# AT32UC3A4256S device description
Architecture: AVR32_UC3; Family: AVR UC3
Registers are 32-bit, read-write, reset 0x0 unless marked. A register's access mark holds for its fields unless they carry their own. Offsets are from the block's base; [hi:lo] are bit positions; {n}, {i} and the like mark numbered series; 'fields as' and 'values as' point back to an identical list.

## USBB — USB 2.0 OTG Interface
Instances: USBB 0xfffe0000, USBB_HSB 0x0000 in hsb
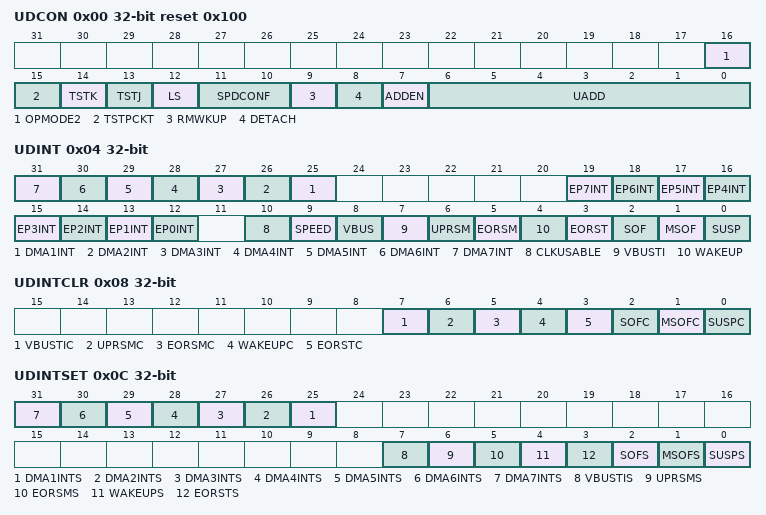
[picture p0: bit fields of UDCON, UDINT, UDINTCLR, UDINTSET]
0x00 UDCON reset 0x100 — Device General Control Register
  [16] OPMODE2, [15] TSTPCKT, [14] TSTK, [13] TSTJ, [12] LS, [11:10] SPDCONF, [9] RMWKUP, [8] DETACH, [7] ADDEN, [6:0] UADD
0x04 UDINT ro — Device Global Interupt Register
  [n+24] DMA{n}INT (n=1..7), [n+12] EP{n}INT (n=0..7), [10] CLKUSABLE, [9] SPEED, [8] VBUS, [7] VBUSTI, [6] UPRSM, [5] EORSM, [4] WAKEUP, [3] EORST, [2] SOF, [1] MSOF, [0] SUSP
0x08 UDINTCLR wo reset not defined — Device Global Interrupt Clear Register
  [7] VBUSTIC, [6] UPRSMC, [5] EORSMC, [4] WAKEUPC, [3] EORSTC, [2] SOFC, [1] MSOFC, [0] SUSPC
0x0C UDINTSET wo reset not defined — Device Global Interrupt Set Regsiter
  [n+24] DMA{n}INTS (n=1..7), [7] VBUSTIS, [6] UPRSMS, [5] EORSMS, [4] WAKEUPS, [3] EORSTS, [2] SOFS, [1] MSOFS, [0] SUSPS
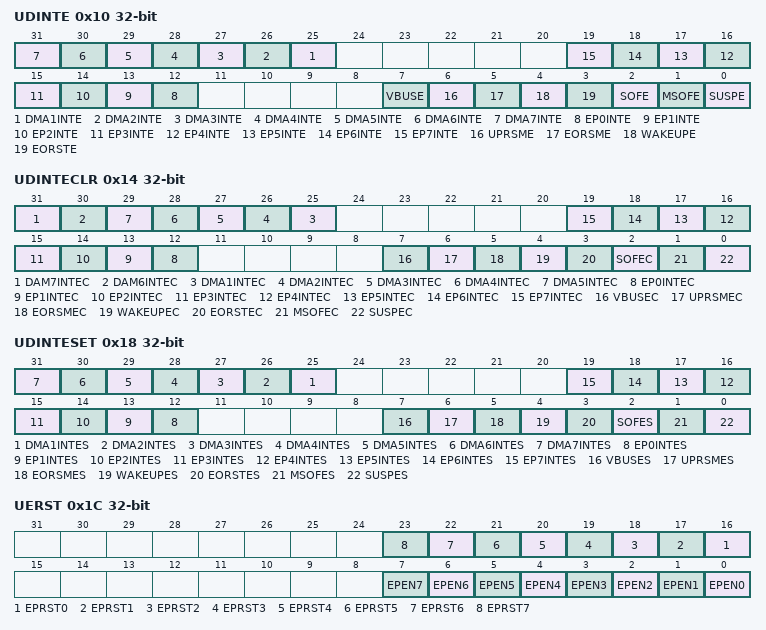
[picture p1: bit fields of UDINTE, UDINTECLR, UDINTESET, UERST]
0x10 UDINTE ro — Device Global Interrupt Enable Register
  [n+24] DMA{n}INTE (n=1..7), [n+12] EP{n}INTE (n=0..7), [7] VBUSE, [6] UPRSME, [5] EORSME, [4] WAKEUPE, [3] EORSTE, [2] SOFE, [1] MSOFE, [0] SUSPE
0x14 UDINTECLR wo reset not defined — Device Global Interrupt Enable Clear Register
  [31] DAM7INTEC, [30] DAM6INTEC, [n+24] DMA{n}INTEC (n=1..5), [n+12] EP{n}INTEC (n=0..7), [7] VBUSEC, [6] UPRSMEC, [5] EORSMEC, [4] WAKEUPEC, [3] EORSTEC, [2] SOFEC, [1] MSOFEC, [0] SUSPEC
0x18 UDINTESET wo reset not defined — Device Global Interrupt Enable Set Register
  [n+24] DMA{n}INTES (n=1..7), [n+12] EP{n}INTES (n=0..7), [7] VBUSES, [6] UPRSMES, [5] EORSMES, [4] WAKEUPES, [3] EORSTES, [2] SOFES, [1] MSOFES, [0] SUSPES
0x1C UERST — Endpoint Enable/Reset Register
  [n+16] EPRST{n} (n=0..7), [n] EPEN{n} (n=0..7)
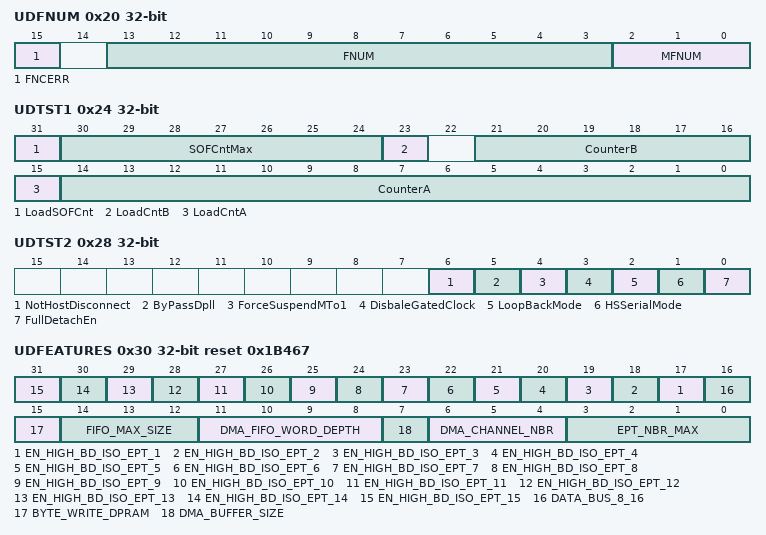
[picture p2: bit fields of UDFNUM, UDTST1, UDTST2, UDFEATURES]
0x20 UDFNUM ro — Device Frame Number Register
  [15] FNCERR, [13:3] FNUM, [2:0] MFNUM
0x24 UDTST1 — Device Test 1 Register
  [31] LoadSOFCnt, [30:24] SOFCntMax, [23] LoadCntB, [21:16] CounterB, [15] LoadCntA, [14:0] CounterA
0x28 UDTST2 — Device Test 2 Register
  [6] NotHostDisconnect, [5] ByPassDpll, [4] ForceSuspendMTo1, [3] DisbaleGatedClock, [2] LoopBackMode, [1] HSSerialMode, [0] FullDetachEn
0x2C UDVERS ro reset 0x260 — Device Version Register
0x30 UDFEATURES ro reset 0x1B467 — Device Feature Register
  [n+16] EN_HIGH_BD_ISO_EPT_{n} (n=1..15)
  [16] DATA_BUS_8_16
  [15] BYTE_WRITE_DPRAM
  [14:12] FIFO_MAX_SIZE
  [11:8] DMA_FIFO_WORD_DEPTH
  [7] DMA_BUFFER_SIZE
    0=16_BITS; 1=24_BITS
  [6:4] DMA_CHANNEL_NBR
  [3:0] EPT_NBR_MAX
0x34 UDADDRSIZE ro reset 0x1000 — Device PB address size
0x38 UDNAME1 ro reset 0x48555342 — IP Name.HUSB
0x3C UDNAME2 ro reset 0x4F5447 — IP Name, OTG
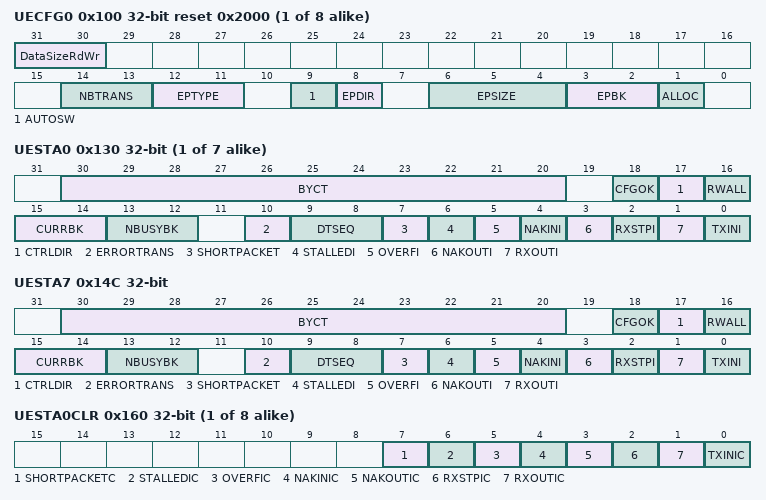
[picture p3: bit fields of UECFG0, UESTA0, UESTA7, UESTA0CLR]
{0x100+4i} UECFG{i} reset 0x2000 (i=0..7) — Endpoint Configuration Register
  [31:30] DataSizeRdWr
  [14:13] NBTRANS
  [12:11] EPTYPE
    0=CONTROL; 1=ISOCHRONOUS; 2=BULK; 3=INTERRUPT
  [9] AUTOSW
  [8] EPDIR
    0=OUT; 1=IN
  [6:4] EPSIZE
    0=8; 1=16; 2=32; 3=64; 4=128; 5=256; 6=512; 7=1024
  [3:2] EPBK
    0=SINGLE; 1=DOUBLE; 2=TRIPLE
  [1] ALLOC
{0x130+4i} UESTA{i} ro (i=0..6) — Endpoint Status Register
  [30:20] BYCT
  [18] CFGOK
  [17] CTRLDIR
    0=OUT; 1=IN
  [16] RWALL
  [15:14] CURRBK
  [13:12] NBUSYBK
  [10] ERRORTRANS
  [9:8] DTSEQ
  [7] SHORTPACKET
  [6] STALLEDI
  [5] OVERFI
  [4] NAKINI
  [3] NAKOUTI
  [2] RXSTPI
  [1] RXOUTI
  [0] TXINI
0x14C UESTA7 ro — Endpoint Status Register
  [30:20] BYCT, [18] CFGOK, [17] CTRLDIR, [16] RWALL, [15:14] CURRBK, [13:12] NBUSYBK, [10] ERRORTRANS, [9:8] DTSEQ, [7] SHORTPACKET, [6] STALLEDI, [5] OVERFI, [4] NAKINI, [3] NAKOUTI, [2] RXSTPI, [1] RXOUTI, [0] TXINI
{0x160+4i} UESTA{i}CLR wo reset not defined (i=0..7) — Endpoint Status Clear Register
  [7] SHORTPACKETC, [6] STALLEDIC, [5] OVERFIC, [4] NAKINIC, [3] NAKOUTIC, [2] RXSTPIC, [1] RXOUTIC, [0] TXINIC
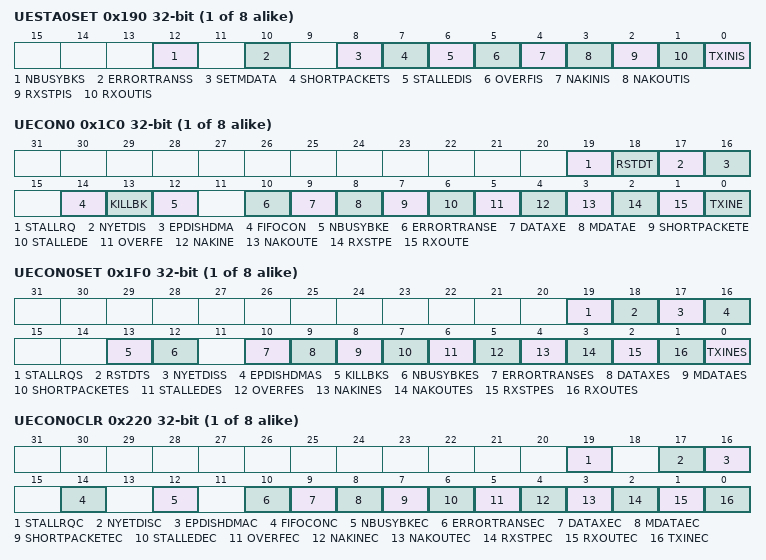
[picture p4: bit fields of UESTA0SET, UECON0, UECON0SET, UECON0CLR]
{0x190+4i} UESTA{i}SET wo reset not defined (i=0..7) — Endpoint Status Set Register
  [12] NBUSYBKS — For test/debug
  [10] ERRORTRANSS — For test/debug
  [8] SETMDATA — For test/debug
  [7] SHORTPACKETS
  [6] STALLEDIS
  [5] OVERFIS
  [4] NAKINIS
  [3] NAKOUTIS
  [2] RXSTPIS
  [1] RXOUTIS
  [0] TXINIS
{0x1C0+4i} UECON{i} ro (i=0..7) — Endpoint Control Register
  [19] STALLRQ, [18] RSTDT, [17] NYETDIS, [16] EPDISHDMA, [14] FIFOCON, [13] KILLBK, [12] NBUSYBKE, [10] ERRORTRANSE, [9] DATAXE, [8] MDATAE, [7] SHORTPACKETE, [6] STALLEDE, [5] OVERFE, [4] NAKINE, [3] NAKOUTE, [2] RXSTPE, [1] RXOUTE, [0] TXINE
{0x1F0+4i} UECON{i}SET wo reset not defined (i=0..7) — Endpoint Control Set Register
  [19] STALLRQS, [18] RSTDTS, [17] NYETDISS, [16] EPDISHDMAS, [13] KILLBKS, [12] NBUSYBKES, [10] ERRORTRANSES, [9] DATAXES, [8] MDATAES, [7] SHORTPACKETES, [6] STALLEDES, [5] OVERFES, [4] NAKINES, [3] NAKOUTES, [2] RXSTPES, [1] RXOUTES, [0] TXINES
{0x220+4i} UECON{i}CLR wo reset not defined (i=0..7) — Endpoint Control Clear Register
  [19] STALLRQC, [17] NYETDISC, [16] EPDISHDMAC, [14] FIFOCONC, [12] NBUSYBKEC, [10] ERRORTRANSEC, [9] DATAXEC, [8] MDATAEC, [7] SHORTPACKETEC, [6] STALLEDEC, [5] OVERFEC, [4] NAKINEC, [3] NAKOUTEC, [2] RXSTPEC, [1] RXOUTEC, [0] TXINEC
{0x250+4i} UEDAT{i} (i=0..7) — Endpoint Data Register
  [31:0] EP_DATA
{0x300+0x10*i} UDDMA{i}_NEXTDESC (i=1..7) — Device DMA Channel Next Descriptor Address
  [31:4] NXT_DESC_ADDR
{0x304+0x10*i} UDDMA{i}_ADDR (i=1..7) — Device DMA Channel HSB Address
  [31:0] HSB_ADDR — HSB bus Address
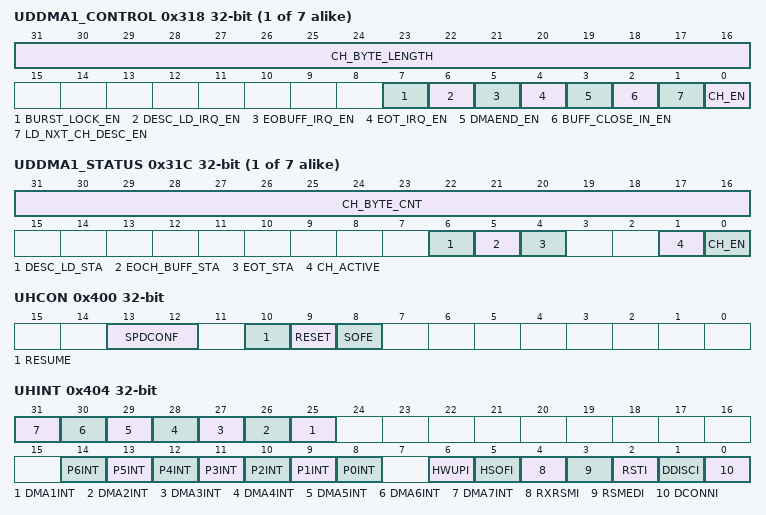
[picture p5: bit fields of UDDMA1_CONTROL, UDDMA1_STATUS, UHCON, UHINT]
{0x308+0x10*i} UDDMA{i}_CONTROL (i=1..7) — Device DMA Channel Control Register
  [31:16] CH_BYTE_LENGTH, [7] BURST_LOCK_EN, [6] DESC_LD_IRQ_EN, [5] EOBUFF_IRQ_EN, [4] EOT_IRQ_EN, [3] DMAEND_EN, [2] BUFF_CLOSE_IN_EN, [1] LD_NXT_CH_DESC_EN, [0] CH_EN
{0x30C+0x10*i} UDDMA{i}_STATUS (i=1..7) — Device DMA Channel Status Register
  [31:16] CH_BYTE_CNT, [6] DESC_LD_STA, [5] EOCH_BUFF_STA, [4] EOT_STA, [1] CH_ACTIVE, [0] CH_EN
0x400 UHCON — Host General Control Register
  [13:12] SPDCONF, [10] RESUME, [9] RESET, [8] SOFE
0x404 UHINT ro — Host Global Interrupt Register
  [n+24] DMA{n}INT (n=1..7), [n+8] P{n}INT (n=0..6), [6] HWUPI, [5] HSOFI, [4] RXRSMI, [3] RSMEDI, [2] RSTI, [1] DDISCI, [0] DCONNI
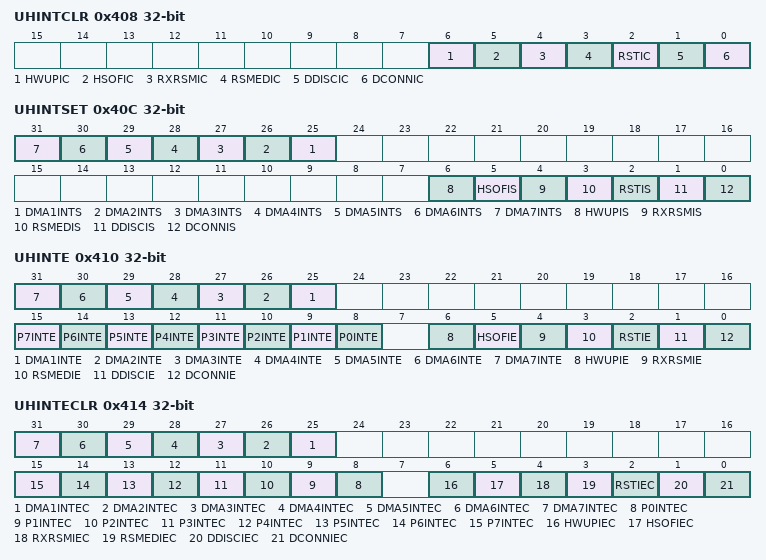
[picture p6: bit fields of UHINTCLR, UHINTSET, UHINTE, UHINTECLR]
0x408 UHINTCLR wo reset not defined — Host Global Interrrupt Clear Register
  [6] HWUPIC, [5] HSOFIC, [4] RXRSMIC, [3] RSMEDIC, [2] RSTIC, [1] DDISCIC, [0] DCONNIC
0x40C UHINTSET wo reset not defined — Host Global Interrupt Set Register
  [n+24] DMA{n}INTS (n=1..7), [6] HWUPIS, [5] HSOFIS, [4] RXRSMIS, [3] RSMEDIS, [2] RSTIS, [1] DDISCIS, [0] DCONNIS
0x410 UHINTE ro — Host Global Interrupt Enable Register
  [n+24] DMA{n}INTE (n=1..7), [n+8] P{n}INTE (n=0..7), [6] HWUPIE, [5] HSOFIE, [4] RXRSMIE, [3] RSMEDIE, [2] RSTIE, [1] DDISCIE, [0] DCONNIE
0x414 UHINTECLR wo reset not defined — Host Global Interrupt Enable Clear Register
  [n+24] DMA{n}INTEC (n=1..7), [n+8] P{n}INTEC (n=0..7), [6] HWUPIEC, [5] HSOFIEC, [4] RXRSMIEC, [3] RSMEDIEC, [2] RSTIEC, [1] DDISCIEC, [0] DCONNIEC
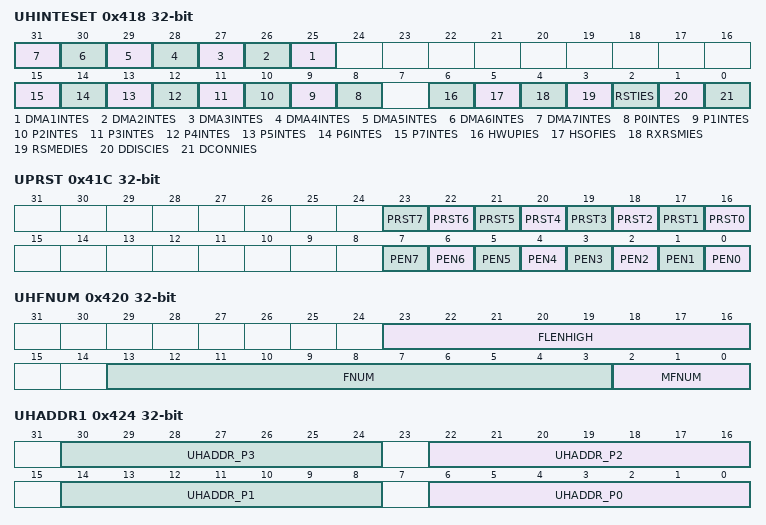
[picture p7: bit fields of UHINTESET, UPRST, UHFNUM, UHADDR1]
0x418 UHINTESET wo reset not defined — Host Global Interrupt Enable Set Register
  [n+24] DMA{n}INTES (n=1..7), [n+8] P{n}INTES (n=0..7), [6] HWUPIES, [5] HSOFIES, [4] RXRSMIES, [3] RSMEDIES, [2] RSTIES, [1] DDISCIES, [0] DCONNIES
0x41C UPRST — Pipe Reset Register
  [n+16] PRST{n} (n=0..7), [n] PEN{n} (n=0..7)
0x420 UHFNUM — Host Frame Number Register
  [23:16] FLENHIGH, [13:3] FNUM, [2:0] MFNUM
0x424 UHADDR1 — USB Host Address
  [8n+6:8n] UHADDR_P{n} (n=0..3) — USB Host Address Pipe{n} (if synthesized)
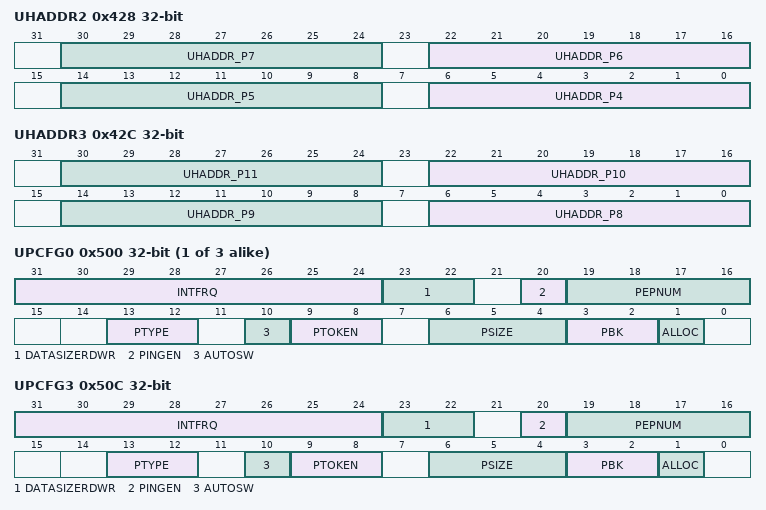
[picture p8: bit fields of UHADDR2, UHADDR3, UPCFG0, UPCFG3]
0x428 UHADDR2 — USB Host Address
  [8n-26:8n-32] UHADDR_P{n} (n=4..7) — USB Host Address Pipe{n} (if synthesized)
0x42C UHADDR3 — USB Host Address
  [8n-58:8n-64] UHADDR_P{n} (n=8..11) — USB Host Address Pipe{n} (if synthesized)
{0x500+4i} UPCFG{i} (i=0..2) — Pipe Configuration Register
  [31:24] INTFRQ
  [23:22] DATASIZERDWR
  [20] PINGEN
  [19:16] PEPNUM
  [13:12] PTYPE
    0=CONTROL; 1=ISOCHRONOUS; 2=BULK; 3=INTERRUPT
  [10] AUTOSW
  [9:8] PTOKEN
    0=SETUP; 1=IN; 2=OUT
  [6:4] PSIZE
    0=8; 1=16; 2=32; 3=64; 4=128; 5=256; 6=512; 7=1024
  [3:2] PBK
    0=SINGLE; 1=DOUBLE; 2=TRIPLE
  [1] ALLOC
0x50C UPCFG3 — Pipe Configuration Register
  [31:24] INTFRQ
  [23:22] DATASIZERDWR
  [20] PINGEN
  [19:16] PEPNUM
  [13:12] PTYPE
    0=CONTROL; 1=ISOCHRONOUS; 2=BULK; 3=INTERRUPT
  [10] AUTOSW
  [9:8] PTOKEN
    0=SETUP; 1=IN; 2=OUT
  [6:4] PSIZE
  [3:2] PBK
    0=SINGLE; 1=DOUBLE; 2=TRIPLE
  [1] ALLOC
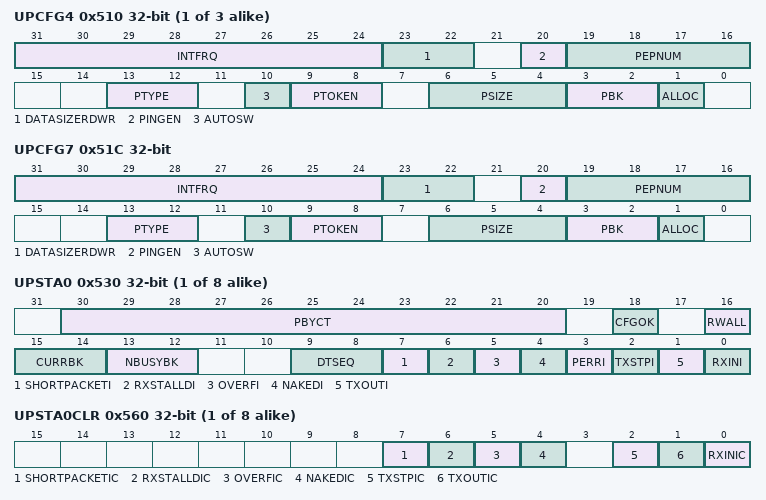
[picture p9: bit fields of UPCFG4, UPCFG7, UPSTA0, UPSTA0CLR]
{0x500+4i} UPCFG{i} (i=4..6) — Pipe Configuration Register
  fields as UPCFG0
0x51C UPCFG7 — Pipe Configuration Register
  [31:24] INTFRQ, [23:22] DATASIZERDWR, [20] PINGEN, [19:16] PEPNUM, [13:12] PTYPE, [10] AUTOSW, [9:8] PTOKEN, [6:4] PSIZE, [3:2] PBK, [1] ALLOC
{0x530+4i} UPSTA{i} ro (i=0..7) — Pipe Status Register
  [30:20] PBYCT, [18] CFGOK, [16] RWALL, [15:14] CURRBK, [13:12] NBUSYBK, [9:8] DTSEQ, [7] SHORTPACKETI, [6] RXSTALLDI, [5] OVERFI, [4] NAKEDI, [3] PERRI, [2] TXSTPI, [1] TXOUTI, [0] RXINI
{0x560+4i} UPSTA{i}CLR wo reset not defined (i=0..7) — Pipe Status Clear Register
  [7] SHORTPACKETIC, [6] RXSTALLDIC, [5] OVERFIC, [4] NAKEDIC, [2] TXSTPIC, [1] TXOUTIC, [0] RXINIC
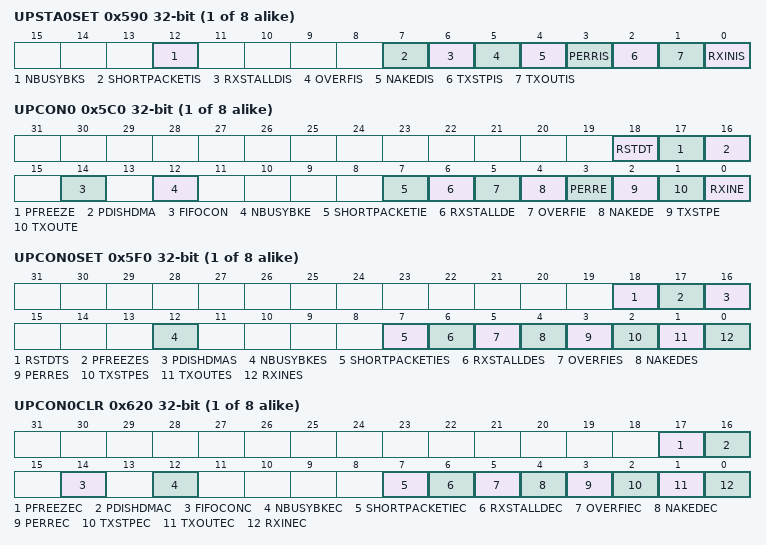
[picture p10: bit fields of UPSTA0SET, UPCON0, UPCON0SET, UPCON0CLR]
{0x590+4i} UPSTA{i}SET wo reset not defined (i=0..7) — Pipe Status Set Register
  [12] NBUSYBKS, [7] SHORTPACKETIS, [6] RXSTALLDIS, [5] OVERFIS, [4] NAKEDIS, [3] PERRIS, [2] TXSTPIS, [1] TXOUTIS, [0] RXINIS
{0x5C0+4i} UPCON{i} ro (i=0..7) — Pipe Control Register
  [18] RSTDT, [17] PFREEZE, [16] PDISHDMA, [14] FIFOCON, [12] NBUSYBKE, [7] SHORTPACKETIE, [6] RXSTALLDE, [5] OVERFIE, [4] NAKEDE, [3] PERRE, [2] TXSTPE, [1] TXOUTE, [0] RXINE
{0x5F0+4i} UPCON{i}SET wo reset not defined (i=0..7) — Pipe Control Set Register
  [18] RSTDTS, [17] PFREEZES, [16] PDISHDMAS, [12] NBUSYBKES, [7] SHORTPACKETIES, [6] RXSTALLDES, [5] OVERFIES, [4] NAKEDES, [3] PERRES, [2] TXSTPES, [1] TXOUTES, [0] RXINES
{0x620+4i} UPCON{i}CLR wo reset not defined (i=0..7) — Pipe Control Clear Register
  [17] PFREEZEC, [16] PDISHDMAC, [14] FIFOCONC, [12] NBUSYBKEC, [7] SHORTPACKETIEC, [6] RXSTALLDEC, [5] OVERFIEC, [4] NAKEDEC, [3] PERREC, [2] TXSTPEC, [1] TXOUTEC, [0] RXINEC
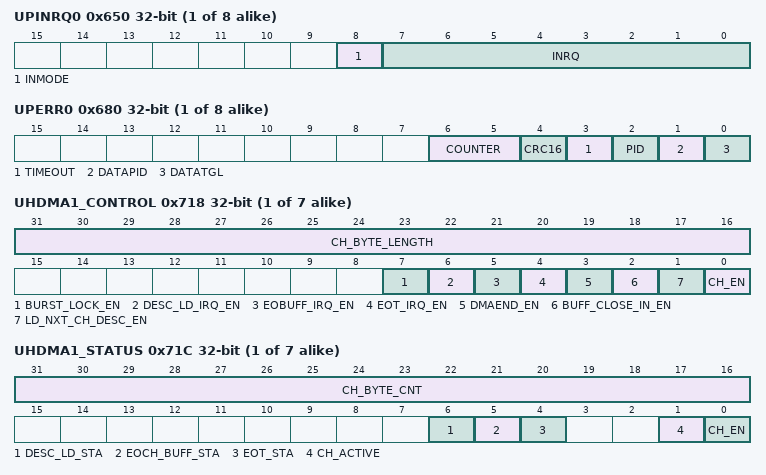
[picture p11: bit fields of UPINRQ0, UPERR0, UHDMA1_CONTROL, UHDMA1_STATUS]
{0x650+4i} UPINRQ{i} (i=0..7) — Pipe In Request
  [8] INMODE, [7:0] INRQ
{0x680+4i} UPERR{i} (i=0..7) — Pipe Error Register
  [6:5] COUNTER, [4] CRC16, [3] TIMEOUT, [2] PID, [1] DATAPID, [0] DATATGL
{0x6B0+4i} UPDAT{i} (i=0..7) — Pipe Data Register
  [31:0] P_DATA
{0x700+0x10*i} UHDMA{i}_NEXTDESC (i=1..7) — Host DMA Channel Next Descriptor Address
  [31:4] NXT_DESC_ADDR
{0x704+0x10*i} UHDMA{i}_ADDR (i=1..7) — Host DMA Channel HSB Address
  [31:0] HSB_ADDR — HSB bus Address
{0x708+0x10*i} UHDMA{i}_CONTROL (i=1..7) — Host DMA Channel Control Register
  fields as UDDMA1_CONTROL
{0x70C+0x10*i} UHDMA{i}_STATUS (i=1..7) — Host DMA Channel Status Register
  fields as UDDMA1_STATUS
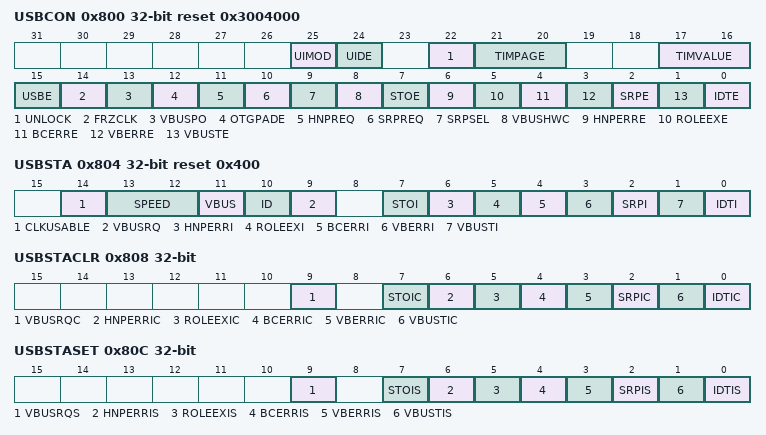
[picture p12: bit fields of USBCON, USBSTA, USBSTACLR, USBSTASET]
0x800 USBCON reset 0x3004000 — General Control Register
  [25] UIMOD
  [24] UIDE
  [22] UNLOCK
  [21:20] TIMPAGE
    0=A_WAIT_VRISE; 1=VB_BUS_PULSING; 2=PD_TMOUT_CNT; 3=SRP_DET_TMOUT
  [17:16] TIMVALUE
  [15] USBE
  [14] FRZCLK
  [13] VBUSPO
  [12] OTGPADE
  [11] HNPREQ
  [10] SRPREQ
  [9] SRPSEL
  [8] VBUSHWC
  [7] STOE
  [6] HNPERRE
  [5] ROLEEXE
  [4] BCERRE
  [3] VBERRE
  [2] SRPE
  [1] VBUSTE
  [0] IDTE
0x804 USBSTA ro reset 0x400 — General Status Register
  [14] CLKUSABLE
  [13:12] SPEED
    0=FULL; 2=LOW
  [11] VBUS
  [10] ID
  [9] VBUSRQ
  [7] STOI
  [6] HNPERRI
  [5] ROLEEXI
  [4] BCERRI
  [3] VBERRI
  [2] SRPI
  [1] VBUSTI
  [0] IDTI
0x808 USBSTACLR wo reset not defined — General Status Clear Register
  [9] VBUSRQC, [7] STOIC, [6] HNPERRIC, [5] ROLEEXIC, [4] BCERRIC, [3] VBERRIC, [2] SRPIC, [1] VBUSTIC, [0] IDTIC
0x80C USBSTASET wo reset not defined — General Status Set Register
  [9] VBUSRQS, [7] STOIS, [6] HNPERRIS, [5] ROLEEXIS, [4] BCERRIS, [3] VBERRIS, [2] SRPIS, [1] VBUSTIS, [0] IDTIS
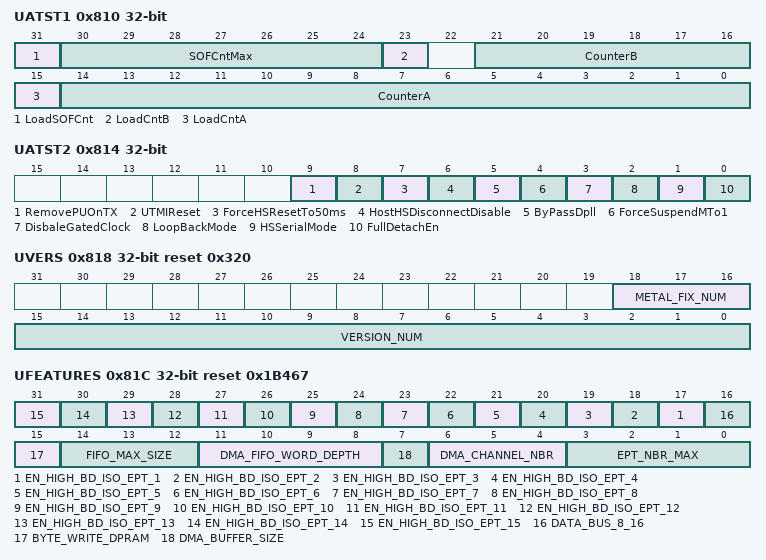
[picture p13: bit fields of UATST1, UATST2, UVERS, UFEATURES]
0x810 UATST1 — Arbiter Test 1 Register
  fields as UDTST1
0x814 UATST2 — Arbiter Test 2 Register
  [9] RemovePUOnTX, [8] UTMIReset, [7] ForceHSResetTo50ms, [6] HostHSDisconnectDisable, [5] ByPassDpll, [4] ForceSuspendMTo1, [3] DisbaleGatedClock, [2] LoopBackMode, [1] HSSerialMode, [0] FullDetachEn
0x818 UVERS ro reset 0x320 — IP Version Register
  [18:16] METAL_FIX_NUM, [15:0] VERSION_NUM
0x81C UFEATURES ro reset 0x1B467 — IP Features Register
  [n+16] EN_HIGH_BD_ISO_EPT_{n} (n=1..15)
  [16] DATA_BUS_8_16
  [15] BYTE_WRITE_DPRAM
  [14:12] FIFO_MAX_SIZE
    0=LT_256; 1=LT_512; 2=LT_1024; 3=LT_2048; 4=LT_4096; 5=LT_8192; 6=LT_16384; 7=GE_16384
  [11:8] DMA_FIFO_WORD_DEPTH
  [7] DMA_BUFFER_SIZE
    0=16_BITS; 1=24_BITS
  [6:4] DMA_CHANNEL_NBR
  [3:0] EPT_NBR_MAX
0x820 UADDRSIZE ro reset 0x1000 — IP PB address size
  [31:0] UADDRSIZE — IP PB Address Size
0x824 UNAME1 ro reset 0x48555342 — IP name, HUSB
0x828 UNAME2 ro reset 0x4F5447 — IP name, OTG
0x82C USBFSM ro reset 0x9 — USB internal finite state machine
  [3:0] DRDSTATE — DualRoleDevice state
    0=A_IDLE; 1=A_WAIT_VRISE; 2=A_WAIT_BCON; 3=A_HOST; 4=A_SUSPEND; 5=A_PERIPHERAL; 6=A_WAIT_VFALL; 7=A_VBUS_ERR; 8=A_WAIT_DISCHARGE; 9=B_IDLE; 10=B_PERIPHERAL; 11=B_WAIT_BEGIN_HNP; 12=B_WAIT_DISCHARGE; 13=B_WAIT_ACON; 14=B_HOST; 15=B_SRP_INIT
